AUTOSAR XML (schema 00049)
package /SwComponent/AdaptiveApplication
  adaptive application sw component type Actuator
    require port ControlData: required-interface=SvControlData
  adaptive application sw component type CM
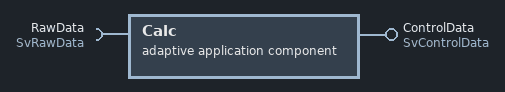
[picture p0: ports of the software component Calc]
  adaptive application sw component type Calc
    provide port ControlData: provided-interface=SvControlData
    require port RawData: required-interface=SvRawData
  adaptive application sw component type EM
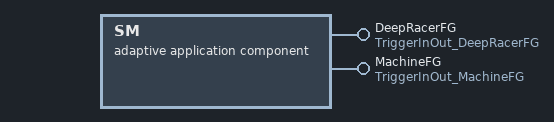
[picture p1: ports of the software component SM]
  adaptive application sw component type SM
    provide port DeepRacerFG: provided-interface=TriggerInOut_DeepRacerFG
    provide port MachineFG: provided-interface=TriggerInOut_MachineFG
  adaptive application sw component type Sensor
    provide port RawData: provided-interface=SvRawData
  adaptive application sw component type SimActuator
    require port ControlData: required-interface=SvControlData
package /SwComponent/Composition
  composition sw component type System
package /AdaptiveApplication/DltConfig
  7 x dlt log channel to process mapping:
    DltLogChannelToProcessMapping_Actuator_TO_Actuator: dlt-log-channel=Actuator, process=Actuator
    DltLogChannelToProcessMapping_CM_TO_CM: dlt-log-channel=CM, process=CM
    DltLogChannelToProcessMapping_Calc_TO_Calc: dlt-log-channel=Calc, process=Calc
    DltLogChannelToProcessMapping_EM_TO_EM: dlt-log-channel=EM, process=EM
    DltLogChannelToProcessMapping_SM_TO_SM: dlt-log-channel=SM, process=SM
    DltLogChannelToProcessMapping_Sensor_TO_Sensor: dlt-log-channel=Sensor, process=Sensor
    DltLogChannelToProcessMapping_SimActuator_TO_SimActuator: dlt-log-channel=SimActuator, process=SimActuator
package /AdaptiveApplication/Executable
  7 x executable, all with logging-behavior=USES-LOGGING, reporting-behavior=REPORTS-EXECUTION-STATE, version=1.0.0:
    Actuator: category=APPLICATION_LEVEL
      root sw component prototype AA: application-type=Actuator
    CM: category=PLATFORM_LEVEL
      root sw component prototype PARA: application-type=CM
    Calc: category=APPLICATION_LEVEL
      root sw component prototype AA: application-type=Calc
    EM: category=PLATFORM_LEVEL
    SM: category=PLATFORM_LEVEL
      root sw component prototype PARA: application-type=SM
    Sensor: category=APPLICATION_LEVEL
      root sw component prototype AA: application-type=Sensor
    SimActuator: category=APPLICATION_LEVEL
      root sw component prototype AA: application-type=SimActuator
package /AdaptiveApplication/Manifest
  7 x service instance to port prototype mapping:
    Actuator_AA_ControlData: port-prototype=AA.ControlData, service-instance=Consumer_SvControlData_AAActuator
    Calc_AA_ControlData: port-prototype=AA.ControlData, service-instance=Provider_SvControlData_AACalc
    Calc_AA_RawData: port-prototype=AA.RawData, service-instance=Consumer_SvRawData_AACalc
    SM_AA_DeepRacerFG: port-prototype=PARA.DeepRacerFG, service-instance=Provider_TriggerInOut_DeepRacerFG_SM
    SM_AA_MachineFG: port-prototype=PARA.MachineFG, service-instance=Provider_TriggerInOut_MachineFG_SM
    Sensor_AA_RawData: port-prototype=AA.RawData, service-instance=Provider_SvRawData_AASensor
    SimActuator_AA_ControlData: port-prototype=AA.ControlData, service-instance=Consumer_SvControlData_AASimActuator
package /AdaptiveApplication/Process
  7 x process:
    Actuator: executable=Actuator, state-dependent-startup-config{function-group-state=DeepRacerFG.Device, resource-group=ResourceGroup, startup-config=Actuator}
      process state machine Actuator: type=ProcessState
    CM: executable=CM, state-dependent-startup-config{function-group-state=[MachineFG.Startup, MachineFG.Restart, MachineFG.Shutdown, MachineFG.Verify], resource-group=ResourceGroup, startup-config=CM}
      process state machine CM: type=ProcessState
    Calc: executable=Calc, state-dependent-startup-config{execution-dependency=CM.Running, function-group-state=MachineFG.Startup, resource-group=ResourceGroup, startup-config=Calc}
      process state machine Calc: type=ProcessState
    EM: executable=EM
      process state machine EM: type=ProcessState
    SM: executable=SM, function-cluster-affiliation=STATE_MANAGEMENT, state-dependent-startup-config{execution-dependency=CM.Running, function-group-state=[MachineFG.Startup, MachineFG.Restart, MachineFG.Shutdown, MachineFG.Verify], resource-group=ResourceGroup, startup-config=SM}
      process state machine SM: type=ProcessState
    Sensor: executable=Sensor, state-dependent-startup-config{execution-dependency=CM.Running, function-group-state=MachineFG.Startup, resource-group=ResourceGroup, startup-config=Sensor}
      process state machine Sensor: type=ProcessState
    SimActuator: executable=SimActuator, state-dependent-startup-config{function-group-state=DeepRacerFG.Simulation, resource-group=ResourceGroup, startup-config=SimActuator}
      process state machine SimActuator: type=ProcessState
package /AdaptiveApplication/StartupConfig
  startup config set StartupConfigSet
    6 x startup config, all with scheduling-policy=SCHED_OTHER, scheduling-priority=0:
      Actuator: timeout=enter-timeout-value=10.0
      CM: timeout=enter-timeout-value=0.0
      Calc: timeout=enter-timeout-value=10.0
      SM: process-argument=device, timeout=enter-timeout-value=0.0
      Sensor: timeout=enter-timeout-value=10.0
      SimActuator: timeout=enter-timeout-value=0.0
package /DataType/Implementation/CPP
  14 x std cpp implementation data type:
    Arithmetic: compu {0=kAdd, 1=kSub, 2=kMul, 3=kDiv}, type-reference=uint8_t
      namespaces:
        symbol props deepracer
        symbol props type
    DeepRacerStateType: compu {0x00=kOff, 0x01=kDevice, 0x02=kSimulation, 0x03=kVerify}, type-reference=uint8_t
      namespaces:
        symbol props ara
        symbol props sm
    MachineStateType: compu {0x00=kOff, 0x01=kStartup, 0x02=kShutdown, 0x03=kRestart, 0x04=kVerify}, type-reference=uint8_t
      namespaces:
        symbol props ara
        symbol props sm
    bool: category=VALUE, type-emitter=FundamentalType
    double: category=VALUE, type-emitter=FundamentalType
    float: category=VALUE, type-emitter=FundamentalType
    int16_t: category=VALUE, header-file=cstdint
    int32_t: category=VALUE, header-file=cstdint
    int64_t: category=VALUE, header-file=cstdint
    int8_t: category=VALUE, header-file=cstdint
    uint16_t: category=VALUE, header-file=cstdint
    uint32_t: category=VALUE, header-file=cstdint
    uint64_t: category=VALUE, header-file=cstdint
    uint8_t: category=VALUE, header-file=cstdint
package /PortInterface/Service
  4 x service interface:
    SvControlData
      namespaces:
        symbol props deepracer
        symbol props service
        symbol props controldata
      events:
        data CEvent: type=CalcDataToActuator
    SvRawData
      namespaces:
        symbol props deepracer
        symbol props service
        symbol props rawdata
      events:
        data REvent: type=SensorDatas
      field RField: type=uint32_t, has-getter=true, has-notifier=true, has-setter=true
      methods:
        operation RMethod: fire-and-forget=false
          4 x arg:
            a: type=double, direction=IN
            arithmetic: type=Arithmetic, direction=IN
            b: type=double, direction=IN
            result: type=double, direction=OUT
    TriggerInOut_DeepRacerFG
      namespaces:
        symbol props ara
        symbol props sm
        symbol props deepracerfg
      field Notifier: type=DeepRacerStateType, has-getter=true, has-notifier=true, has-setter=false
      field Trigger: type=DeepRacerStateType, has-getter=false, has-notifier=false, has-setter=true
    TriggerInOut_MachineFG
      namespaces:
        symbol props ara
        symbol props sm
        symbol props machinefg
      field Notifier: type=MachineStateType, has-getter=true, has-notifier=true, has-setter=false
      field Trigger: type=MachineStateType, has-getter=false, has-notifier=false, has-setter=true
package /Platform
  machine Machine: machine-design=Ecu, trusted-platform-executable-launch-behavior=NO-TRUSTED-PLATFORM-SUPPORT
    module-instantiations:
      os module instantiation Linux
        resource group ResourceGroup
      log and trace instantiation LogAndTraceInstantiation: dlt-ecu-id=ECU
        7 x dlt log channel, all with log-trace-log-modes=CONSOLE:
          Actuator: application-id=ACTR, context-id=ACTR, log-trace-default-log-level=INFO
          CM: application-id=CM, context-id=CM, log-trace-default-log-level=ERROR
          Calc: application-id=CALC, context-id=CALC, log-trace-default-log-level=INFO
          EM: application-id=EM, context-id=EM, log-trace-default-log-level=ERROR
          SM: application-id=SM, context-id=SM, log-trace-default-log-level=INFO
          Sensor: application-id=SENS, context-id=SENS, log-trace-default-log-level=INFO
          SimActuator: application-id=SACT, context-id=SACT, log-trace-default-log-level=INFO
    processor Atom  # Intel Atom
      processor core Core0: core-id=0
      processor core Core2: core-id=2
package /Platform/FunctionGroup
  function group set FunctionGroupSet
    function-groups:
      mode declaration group prototype DeepRacerFG: type=DeepRacerState
      mode declaration group prototype MachineFG: type=MachineState
package /Platform/ProcessToMachine
  process to machine mapping set ProcessToMachineMappingSet
    7 x process to machine mapping, all with machine=Machine:
      ProcessToMachineMapping_Actuator_TO_Machine_TO_UnknownModule: process=Actuator
      ProcessToMachineMapping_CM_TO_Machine_TO_UnknownModule: process=CM
      ProcessToMachineMapping_Calc_TO_Machine_TO_UnknownModule: process=Calc
      ProcessToMachineMapping_EM_TO_Machine_TO_UnknownModule: process=EM
      ProcessToMachineMapping_SM_TO_Machine_TO_UnknownModule: process=SM
      ProcessToMachineMapping_Sensor_TO_Machine_TO_UnknownModule: process=Sensor
      ProcessToMachineMapping_SimActuator_TO_Machine_TO_UnknownModule: process=SimActuator
package /System
  system DeepRacerVehicle: category=MACHINE_DESIGN_EXTRACT, system-version=1.0.0  # AWS DeepRacer Evo
package /System/Service/Deployment
  someip service interface deployment SvControlData: service-interface=SvControlData, service-interface-id=82, service-interface-version={major-version=1, minor-version=0}
    someip event deployment CEvent: event=CEvent, event-id=1, transport-protocol=UDP
    someip event group Eventgroup_CEvent: event-group-id=1, event=CEvent
  someip service interface deployment SvRawData: service-interface=SvRawData, service-interface-id=81, service-interface-version={major-version=1, minor-version=0}
    someip event deployment REvent: event=REvent, event-id=1, transport-protocol=UDP
    someip field deployment RField: field=RField
      get Get_RField: method-id=2, transport-protocol=UDP
      notifier Notification_RField: event-id=2, transport-protocol=UDP
      set Set_RField: method-id=3, transport-protocol=UDP
    someip method deployment RMethod: method=RMethod, method-id=1, transport-protocol=UDP
    someip event group Eventgroup_Notification_RField: event-group-id=2, event=Notification_RField
    someip event group Eventgroup_REvent: event-group-id=1, event=REvent
  user defined service interface deployment TriggerInOut_DeepRacerFG: category=SERVICE_INTERFACE_DEPLOYMENT_IPC, service-interface=TriggerInOut_DeepRacerFG
    user defined field deployment Notifier: field=TriggerInOut_DeepRacerFG/Notifier
      get Get_Notifier
      notifier Notification_Notifier
    user defined field deployment Trigger: field=TriggerInOut_DeepRacerFG/Trigger
      set Set_Trigger
  user defined service interface deployment TriggerInOut_MachineFG: category=SERVICE_INTERFACE_DEPLOYMENT_IPC, service-interface=TriggerInOut_MachineFG
    user defined field deployment Notifier: field=TriggerInOut_MachineFG/Notifier
      get Get_Notifier
      notifier Notification_Notifier
    user defined field deployment Trigger: field=TriggerInOut_MachineFG/Trigger
      set Set_Trigger
package /System/Service/Endpoint
  5 x someip service instance to machine mapping, all with communication-connector=wlo1:
    Mapping_Consumer_SvControlData_AAActuator: service-instance=Consumer_SvControlData_AAActuator, tcp-port=21013, udp-port=21013
    Mapping_Consumer_SvControlData_AASimActuator: service-instance=Consumer_SvControlData_AASimActuator, tcp-port=21012, udp-port=21012
    Mapping_Consumer_SvRawData_AACalc: service-instance=Consumer_SvRawData_AACalc, tcp-port=21011, udp-port=21011
    Mapping_Provider_SvControlData_AACalc: service-instance=Provider_SvControlData_AACalc, tcp-port=21002, udp-port=21002
    Mapping_Provider_SvRawData_AASensor: service-instance=Provider_SvRawData_AASensor, tcp-port=21001, udp-port=21001
  user defined service instance to machine mapping Mapping_Provider_TriggerInOut_DeepRacerFG_SM: communication-connector=IPC, service-instance=Provider_TriggerInOut_DeepRacerFG_SM
  user defined service instance to machine mapping Mapping_Provider_TriggerInOut_MachineFG_SM: communication-connector=IPC, service-instance=Provider_TriggerInOut_MachineFG_SM
package /System/Service/Instance
  required someip service instance Consumer_SvControlData_AAActuator: service-interface-deployment=SvControlData, required-minor-version=ANY, required-service-instance-id=1, sd-client-config=SdClientConfig, version-driven-find-behavior=EXACT-OR-ANY-MINOR-VERSION
    someip required event group Eventgroup_CEvent: event-group=Eventgroup_CEvent, sd-client-event-group-timing-config=SubscriptionTimingConfig
  required someip service instance Consumer_SvControlData_AASimActuator: service-interface-deployment=SvControlData, required-minor-version=ANY, required-service-instance-id=1, sd-client-config=SdClientConfig, version-driven-find-behavior=EXACT-OR-ANY-MINOR-VERSION
    someip required event group Eventgroup_CEvent: event-group=Eventgroup_CEvent, sd-client-event-group-timing-config=SubscriptionTimingConfig
  required someip service instance Consumer_SvRawData_AACalc: service-interface-deployment=SvRawData, method-request-propss=[Get_RField, Set_RField, RMethod], required-minor-version=ANY, required-service-instance-id=1, sd-client-config=SdClientConfig, version-driven-find-behavior=EXACT-OR-ANY-MINOR-VERSION
    someip required event group Eventgroup_Notification_RField: event-group=Eventgroup_Notification_RField, sd-client-event-group-timing-config=SubscriptionTimingConfig
    someip required event group Eventgroup_REvent: event-group=Eventgroup_REvent, sd-client-event-group-timing-config=SubscriptionTimingConfig
  provided someip service instance Provider_SvControlData_AACalc: service-interface-deployment=SvControlData, someip-event-props=CEvent, sd-server-config=SdServerConfig, service-instance-id=1
    someip provided event group Eventgroup_CEvent: event-group=Eventgroup_CEvent, multicast-threshold=0
  provided someip service instance Provider_SvRawData_AASensor: service-interface-deployment=SvRawData, event-propss=[REvent, Notification_RField], method-response-propss=[Get_RField, Set_RField, RMethod], sd-server-config=SdServerConfig, service-instance-id=1
    someip provided event group Eventgroup_Notification_RField: event-group=Eventgroup_Notification_RField, multicast-threshold=0
    someip provided event group Eventgroup_REvent: event-group=Eventgroup_REvent, multicast-threshold=0
  provided user defined service instance Provider_TriggerInOut_DeepRacerFG_SM: service-interface-deployment=TriggerInOut_DeepRacerFG
  provided user defined service instance Provider_TriggerInOut_MachineFG_SM: service-interface-deployment=TriggerInOut_MachineFG
package /System/Service/TimingConfig
  someip sd client service instance config SdClientConfig: initial-find-behavior={initial-delay-max-value=0.2, initial-delay-min-value=0.1, initial-repetitions-base-delay=0.1, initial-repetitions-max=4}, service-find-time-to-live=16777215
  someip sd server service instance config SdServerConfig: initial-offer-behavior={initial-delay-max-value=0.2, initial-delay-min-value=0.1, initial-repetitions-base-delay=0.1, initial-repetitions-max=3}, offer-cyclic-delay=0.5, request-response-delay={max-value=0.0, min-value=0.0}, service-offer-time-to-live=16777215
  someip sd client event group timing config SubscriptionTimingConfig: request-response-delay={max-value=0.0, min-value=0.0}, time-to-live=16777215
package /System/VehicleTopology/Cluster
  ethernet cluster EthernetCluster  # DeepRacer IP address
    ethernet physical channel PhysicalChannel: category=WIRED, comm-connectors=wlo1
      network endpoint EcuEndpoint: network-endpoint-addresses=ipv-4-configuration={ipv-4-address=192.168.20.27, ipv-4-address-source=FIXED}
      network endpoint SdEndpoint: network-endpoint-addresses=ipv-4-configuration={ipv-4-address=224.0.0.1, ipv-4-address-source=FIXED}
package /System/VehicleTopology/Ecu
  machine design Ecu: service-discover-configs=someip-service-discovery={multicast-sd-ip-address=SdEndpoint, someip-service-discovery-port=30490}  # DeepRacer Network Node - Ethernet: To communicate with Simulator - IPC: To communicate between internal AA
    user defined communication connector IPC
    ethernet communication connector wlo1: unicast-network-endpoint=EcuEndpoint
package /StateMachine
  mode declaration group DeepRacerState: initial-mode=DeepRacerState/Off
    4 x mode:
      Device
      Off
      Simulation
      Verify
  mode declaration group MachineState: initial-mode=MachineState/Off
    5 x mode:
      Off
      Restart
      Shutdown
      Startup
      Verify
  mode declaration group ProcessState: initial-mode=Idle
    4 x mode:
      Idle
      Running
      Starting
      Terminated
package /UnsetARElements
  6 x std cpp implementation data type:
    CalcDataToActuator: category=STRUCTURE
      namespaces:
        symbol props deepracer
        symbol props type
      cpp implementation data type element cur_speed: type-reference=float
      cpp implementation data type element cur_angle: type-reference=float
    LidarDataForUser: category=STRUCTURE
      namespaces:
        symbol props deepracer
        symbol props type
      4 x cpp implementation data type element:
        sync: type-reference=uint32_t
        theta: type-reference=double
        dist: type-reference=double
        quality: type-reference=uint32_t
    SensorDatas: category=STRUCTURE
      namespaces:
        symbol props deepracer
        symbol props type
      cpp implementation data type element lidars: type-reference=lidars
      cpp implementation data type element left_camera: type-reference=left_camera
      cpp implementation data type element right_camera: type-reference=right_camera
    left_camera: category=VECTOR, cpp-template-argument=uint8_t
      namespaces:
        symbol props deepracer
        symbol props type
    lidars: category=VECTOR, cpp-template-argument=LidarDataForUser
      namespaces:
        symbol props deepracer
        symbol props type
    right_camera: category=VECTOR, cpp-template-argument=uint8_t
      namespaces:
        symbol props deepracer
        symbol props type
